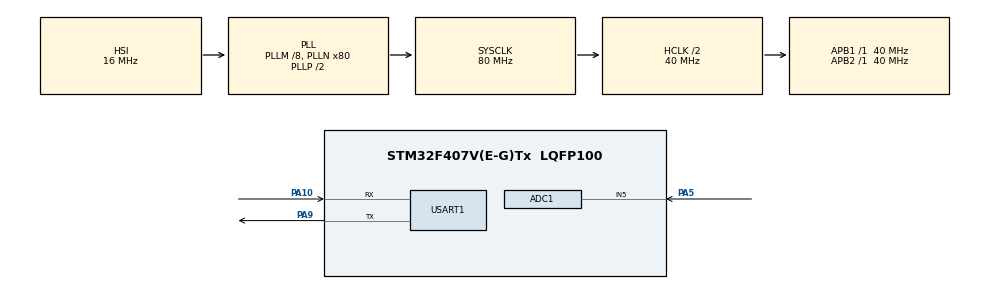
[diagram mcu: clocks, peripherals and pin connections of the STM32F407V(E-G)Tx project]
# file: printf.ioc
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ADC1.Channel-0\#ChannelRegularConversion=ADC_CHANNEL_5
ADC1.ContinuousConvMode=ENABLE
ADC1.DMAContinuousRequests=ENABLE
ADC1.NbrOfConversionFlag=1
ADC1.Rank-0\#ChannelRegularConversion=1
ADC1.SamplingTime-0\#ChannelRegularConversion=ADC_SAMPLETIME_3CYCLES
ADC1.master=1
Dma.ADC1.0.Direction=DMA_PERIPH_TO_MEMORY
Dma.ADC1.0.FIFOMode=DMA_FIFOMODE_DISABLE
Dma.ADC1.0.Instance=DMA2_Stream0
Dma.ADC1.0.MemDataAlignment=DMA_MDATAALIGN_HALFWORD
Dma.ADC1.0.MemInc=DMA_MINC_ENABLE
Dma.ADC1.0.Mode=DMA_CIRCULAR
Dma.ADC1.0.PeriphDataAlignment=DMA_PDATAALIGN_HALFWORD
Dma.ADC1.0.PeriphInc=DMA_PINC_DISABLE
Dma.ADC1.0.Priority=DMA_PRIORITY_LOW
Dma.Request0=ADC1
Mcu.Family=STM32F4
Mcu.Name=STM32F407V(E-G)Tx
Mcu.Package=LQFP100
NVIC.ADC_IRQn=true\:0\:0\:false\:false\:true\:true\:true\:true
NVIC.DMA2_Stream0_IRQn=true\:0\:0\:false\:false\:true\:false\:true\:true
NVIC.PriorityGroup=NVIC_PRIORITYGROUP_4
NVIC.USART1_IRQn=true\:0\:0\:false\:false\:true\:true\:true\:true
PA10.Mode=Asynchronous
PA10.Signal=USART1_RX
PA5.Signal=ADCx_IN5
PA9.Mode=Asynchronous
PA9.Signal=USART1_TX
PH0-OSC_IN.Mode=HSE-External-Oscillator
PH0-OSC_IN.Signal=RCC_OSC_IN
PH1-OSC_OUT.Mode=HSE-External-Oscillator
PH1-OSC_OUT.Signal=RCC_OSC_OUT
ProjectManager.HeapSize=0x200
ProjectManager.StackSize=0x400
ProjectManager.TargetToolchain=STM32CubeIDE
RCC.48MHZClocksFreq_Value=40000000
RCC.AHBCLKDivider=RCC_SYSCLK_DIV2
RCC.AHBFreq_Value=40000000
RCC.APB1Freq_Value=40000000
RCC.APB1TimFreq_Value=40000000
RCC.APB2Freq_Value=40000000
RCC.APB2TimFreq_Value=40000000
RCC.CortexFreq_Value=40000000
RCC.HCLKFreq_Value=40000000
RCC.HSE_VALUE=25000000
RCC.HSI_VALUE=16000000
RCC.LSE_VALUE=32768
RCC.PLLM=8
RCC.PLLN=80
RCC.SYSCLKFreq_VALUE=80000000
RCC.SYSCLKSource=RCC_SYSCLKSOURCE_PLLCLK
RCC.VCOOutputFreq_Value=160000000
SH.ADCx_IN5.0=ADC1_IN5,IN5
USART1.VirtualMode=VM_ASYNC
board=custom

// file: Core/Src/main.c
/* USER CODE BEGIN Header */
/**
  ******************************************************************************
  * @file           : main.c
  * @brief          : Main program body
  ******************************************************************************
  * @attention
  *
  * Copyright (c) 2024 STMicroelectronics.
  * All rights reserved.
  *
  * This software is licensed under terms that can be found in the LICENSE file
  * in the root directory of this software component.
  * If no LICENSE file comes with this software, it is provided AS-IS.
  *
  ******************************************************************************
  */
/* USER CODE END Header */
#include "main.h"

/* USER CODE BEGIN Includes */
#include "stdio.h"
/* USER CODE END Includes */

ADC_HandleTypeDef hadc1;
DMA_HandleTypeDef hdma_adc1;

UART_HandleTypeDef huart1;

void SystemClock_Config(void);
static void MX_GPIO_Init(void);
static void MX_DMA_Init(void);
static void MX_USART1_UART_Init(void);
static void MX_ADC1_Init(void);
/* USER CODE BEGIN PFP */
#ifdef __GNUC__									//串口重定�???
#define PUTCHAR_PROTOTYPE int __io_putchar(int ch)
#else
#define PUTCHAR_PROTOTYPE int fputc(int ch, FILE *f)
#endif
PUTCHAR_PROTOTYPE
{
    HAL_UART_Transmit(&huart1 , (uint8_t *)&ch, 1, 0xFFFF);
    return ch;
}

/* USER CODE END PFP */

/* USER CODE BEGIN 0 */

float Voltage;  //电压

uint32_t AD_value = 0;
float f_AD_value = 0.0;

	// DMA完成转换后的回调函数
	void HAL_ADC_ConvCpltCallback(ADC_HandleTypeDef* hadc) {
	    if (hadc->Instance == ADC1) {
	        // 将ADC值转换为电压
	        f_AD_value = AD_value * 3.3 / 4096;
	        // 打印结果
	        printf("AD_value=%d\r\n", AD_value);
	        printf("f_AD_value=%.3f\r\n", f_AD_value);
	    }
	}

/* USER CODE END 0 */

int main(void)
{

  /* MCU Configuration--------------------------------------------------------*/

  /* Reset of all peripherals, Initializes the Flash interface and the Systick. */
  HAL_Init();

  /* Configure the system clock */
  SystemClock_Config();

  /* Initialize all configured peripherals */
  MX_GPIO_Init();
  MX_DMA_Init();
  MX_USART1_UART_Init();
  MX_ADC1_Init();
  /* USER CODE BEGIN 2 */

	HAL_ADC_Start_DMA(&hadc1, (uint32_t*)&AD_value, 1);

  /* USER CODE END 2 */

  /* Infinite loop */
  /* USER CODE BEGIN WHILE */
  while (1)
  {/*
	    //printf("正常打印");
	  	HAL_ADC_Start_DMA(&hadc1, (uint32_t*)&AD_value, 1);                       // 启动ADC
		HAL_ADC_PollForConversion(&hadc1, 10);        // 等待转换完成
		HAL_ADC_Stop(&hadc1);                         // 关闭ADC
		AD_value = HAL_ADC_GetValue(&hadc1);          // 获取ADC�???
		f_AD_value = AD_value * 3.3 / 4096;           // 将ADC值转换成电压�???
		printf("AD_value=%d\r\n", AD_value);          // 打印原始ADC�???
		printf("f_AD_value=%.3f\r\n", f_AD_value);    // 打印转换后的电压�???
		HAL_Delay(500);                               // 加入延时便于观察
	*/

	  HAL_Delay(500);  // 加入延时便于观察

    /* USER CODE END WHILE */

  }
}

void SystemClock_Config(void)
{
  RCC_OscInitTypeDef RCC_OscInitStruct = {0};
  RCC_ClkInitTypeDef RCC_ClkInitStruct = {0};

  /** Configure the main internal regulator output voltage
  */
  __HAL_RCC_PWR_CLK_ENABLE();
  __HAL_PWR_VOLTAGESCALING_CONFIG(PWR_REGULATOR_VOLTAGE_SCALE1);

  /** Initializes the RCC Oscillators according to the specified parameters
  * in the RCC_OscInitTypeDef structure.
  */
  RCC_OscInitStruct.OscillatorType = RCC_OSCILLATORTYPE_HSI;
  RCC_OscInitStruct.HSIState = RCC_HSI_ON;
  RCC_OscInitStruct.HSICalibrationValue = RCC_HSICALIBRATION_DEFAULT;
  RCC_OscInitStruct.PLL.PLLState = RCC_PLL_ON;
  RCC_OscInitStruct.PLL.PLLSource = RCC_PLLSOURCE_HSI;
  RCC_OscInitStruct.PLL.PLLM = 8;
  RCC_OscInitStruct.PLL.PLLN = 80;
  RCC_OscInitStruct.PLL.PLLP = RCC_PLLP_DIV2;
  RCC_OscInitStruct.PLL.PLLQ = 4;
  if (HAL_RCC_OscConfig(&RCC_OscInitStruct) != HAL_OK)
  {
    Error_Handler();
  }

  /** Initializes the CPU, AHB and APB buses clocks
  */
  RCC_ClkInitStruct.ClockType = RCC_CLOCKTYPE_HCLK|RCC_CLOCKTYPE_SYSCLK
                              |RCC_CLOCKTYPE_PCLK1|RCC_CLOCKTYPE_PCLK2;
  RCC_ClkInitStruct.SYSCLKSource = RCC_SYSCLKSOURCE_PLLCLK;
  RCC_ClkInitStruct.AHBCLKDivider = RCC_SYSCLK_DIV2;
  RCC_ClkInitStruct.APB1CLKDivider = RCC_HCLK_DIV1;
  RCC_ClkInitStruct.APB2CLKDivider = RCC_HCLK_DIV1;

  if (HAL_RCC_ClockConfig(&RCC_ClkInitStruct, FLASH_LATENCY_1) != HAL_OK)
  {
    Error_Handler();
  }
}

static void MX_ADC1_Init(void)
{

  ADC_ChannelConfTypeDef sConfig = {0};

  /** Configure the global features of the ADC (Clock, Resolution, Data Alignment and number of conversion)
  */
  hadc1.Instance = ADC1;
  hadc1.Init.ClockPrescaler = ADC_CLOCK_SYNC_PCLK_DIV2;
  hadc1.Init.Resolution = ADC_RESOLUTION_12B;
  hadc1.Init.ScanConvMode = DISABLE;
  hadc1.Init.ContinuousConvMode = ENABLE;
  hadc1.Init.DiscontinuousConvMode = DISABLE;
  hadc1.Init.ExternalTrigConvEdge = ADC_EXTERNALTRIGCONVEDGE_NONE;
  hadc1.Init.ExternalTrigConv = ADC_SOFTWARE_START;
  hadc1.Init.DataAlign = ADC_DATAALIGN_RIGHT;
  hadc1.Init.NbrOfConversion = 1;
  hadc1.Init.DMAContinuousRequests = ENABLE;
  hadc1.Init.EOCSelection = ADC_EOC_SINGLE_CONV;
  if (HAL_ADC_Init(&hadc1) != HAL_OK)
  {
    Error_Handler();
  }

  /** Configure for the selected ADC regular channel its corresponding rank in the sequencer and its sample time.
  */
  sConfig.Channel = ADC_CHANNEL_5;
  sConfig.Rank = 1;
  sConfig.SamplingTime = ADC_SAMPLETIME_3CYCLES;
  if (HAL_ADC_ConfigChannel(&hadc1, &sConfig) != HAL_OK)
  {
    Error_Handler();
  }

}

static void MX_USART1_UART_Init(void)
{

  huart1.Instance = USART1;
  huart1.Init.BaudRate = 115200;
  huart1.Init.WordLength = UART_WORDLENGTH_8B;
  huart1.Init.StopBits = UART_STOPBITS_1;
  huart1.Init.Parity = UART_PARITY_NONE;
  huart1.Init.Mode = UART_MODE_TX_RX;
  huart1.Init.HwFlowCtl = UART_HWCONTROL_NONE;
  huart1.Init.OverSampling = UART_OVERSAMPLING_16;
  if (HAL_UART_Init(&huart1) != HAL_OK)
  {
    Error_Handler();
  }

}

static void MX_DMA_Init(void)
{

  /* DMA controller clock enable */
  __HAL_RCC_DMA2_CLK_ENABLE();

  /* DMA interrupt init */
  /* DMA2_Stream0_IRQn interrupt configuration */
  HAL_NVIC_SetPriority(DMA2_Stream0_IRQn, 0, 0);
  HAL_NVIC_EnableIRQ(DMA2_Stream0_IRQn);

}

static void MX_GPIO_Init(void)
{

  /* GPIO Ports Clock Enable */
  __HAL_RCC_GPIOH_CLK_ENABLE();
  __HAL_RCC_GPIOA_CLK_ENABLE();

}

void Error_Handler(void)
{
  __disable_irq();
  while (1)
  {
  }
}
